# MCXA156 register map
Vendor: nxp.com; File version: 1.0
CPU: CM33 r2p0, little endian, no MPU, FPU, VTOR, 3 interrupt priority bits
Registers are 32-bit, read-write, reset 0x0 unless marked. A register's access mark holds for its fields unless they carry their own. Offsets are from the block's base; [hi:lo] are bit positions; {n}, {i} and the like mark numbered series.

## CMP0 — LPCMP
Base 0x400B1000
Same registers: CMP1 0x400B2000
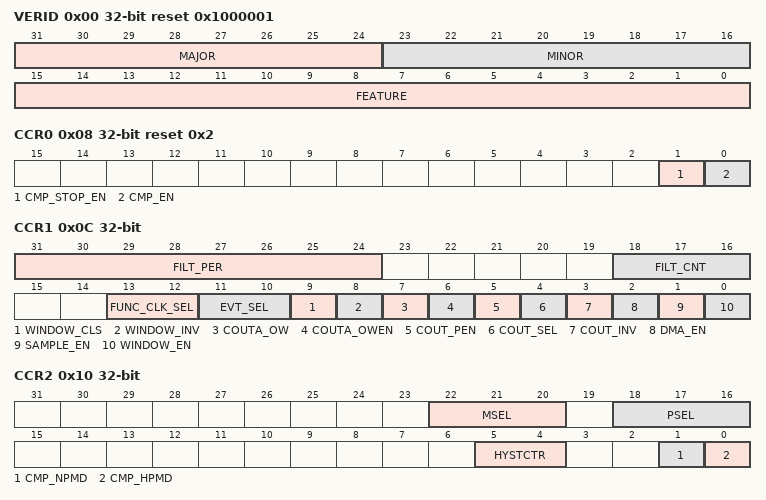
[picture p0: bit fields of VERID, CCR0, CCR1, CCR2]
0x00 VERID ro reset 0x1000001 — Version ID
  [31:24] MAJOR — Major Version Number
  [23:16] MINOR — Minor Version Number
  [15:0] FEATURE — Feature Specification Number
    1=ROUND_ROBIN (Round robin feature)
0x04 PARAM ro reset 0x2 — Parameter
  [3:0] DAC_RES — DAC Resolution
    0=RESO_4 (4-bit DAC); 1=RESO_6 (6-bit DAC); 2=RESO_8 (8-bit DAC); 3=RESO_10 (10-bit DAC); 4=RESO_12 (12-bit DAC); 5=RESO_14 (14-bit DAC); 6=RESO_16 (16-bit DAC)
0x08 CCR0 reset 0x2 — Comparator Control Register 0
  [1] CMP_STOP_EN — Comparator Deep Sleep Mode Enable
    0=DISABLE (Disables the analog comparator regardless of CMP_EN.); 1=ENABLE (Allows CMP_EN to enable the analog comparator.)
  [0] CMP_EN — Comparator Enable
    0=DISABLE (Disable (The analog logic remains off and consumes no power.)); 1=ENABLE
0x0C CCR1 — Comparator Control Register 1
  [31:24] FILT_PER — Filter Sample Period
  [18:16] FILT_CNT — Filter Sample Count
    0=BYPASSED (Filter is bypassed: COUT = COUTA); 1=SAMPLE_1 (1 consecutive sample (Comparator output is simply sampled.)); {v}=SAMPLE_{v} ({v} consecutive samples) (v=2..7)
  [13:12] FUNC_CLK_SEL — Functional Clock Source Select
    {v}=FUNC{v} (Select functional clock source {v}) (v=0..3)
  [11:10] EVT_SEL — COUT Event Select
    0=RISING (Rising edge); 1=FALLING (Falling edge); 0b1x=BOTH (Both edges)
  [9] WINDOW_CLS — COUT Event Window Close
    0=NO_CLOSE (COUT event cannot close the window); 1=CLOSE (COUT event can close the window)
  [8] WINDOW_INV — WINDOW/SAMPLE Signal Invert
    0=NO_INVERT (Do not invert); 1=INVERT
  [7] COUTA_OW — COUTA Output Level for Closed Window
    0=COUTA_0 (COUTA is 0); 1=COUTA_1 (COUTA is 1)
  [6] COUTA_OWEN — COUTA_OW Enable
    0=SAMPLED (COUTA holds the last sampled value.); 1=COUTA_OW (Enables the COUTA signal value to be defined by COUTA_OW.)
  [5] COUT_PEN — Comparator Output Pin Enable
    0=UNAVAILABLE (Not available); 1=AVAILABLE
  [4] COUT_SEL — Comparator Output Select
    0=COUT (Use COUT (filtered)); 1=COUTA (Use COUTA (unfiltered))
  [3] COUT_INV — Comparator Invert
    0=NO_INVERT (Do not invert); 1=INVERT
  [2] DMA_EN — DMA Enable
    0=DISABLE; 1=ENABLE
  [1] SAMPLE_EN — Sampling Enable
    0=DISABLE; 1=ENABLE
  [0] WINDOW_EN — Windowing Enable
    0=DISABLE; 1=ENABLE
0x10 CCR2 — Comparator Control Register 2
  [22:20] MSEL — Minus Input MUX Select
    {v}=INPUT_{v} (Input {v}m) (v=0..5); 7=INPUT_7 (Internal DAC output)
  [18:16] PSEL — Plus Input MUX Select
    {v}=INPUT_{v} (Input {v}p) (v=0..5); 7=INPUT_7 (Internal DAC output)
  [5:4] HYSTCTR — Comparator Hysteresis Control
    0=LEVEL_0 (Level 0: Analog comparator hysteresis 0 mV.); 1=LEVEL_1 (Level 1: Analog comparator hysteresis 10 mV.); 2=LEVEL_2 (Level 2: Analog comparator hysteresis 20 mV.); 3=LEVEL_3 (Level 3: Analog comparator hysteresis 30 mV.)
  [1] CMP_NPMD — CMP Nano Power Mode Select
    0=NO_NANO (Disables CMP Nano power mode. CCR2[CMP_HPMD] determines the mode for the comparator.); 1=NANO (Enables CMP Nano power mode.)
  [0] CMP_HPMD — CMP High Power Mode Select
    0=LOW (Low power (speed) comparison mode); 1=HIGH (High power (speed) comparison mode)
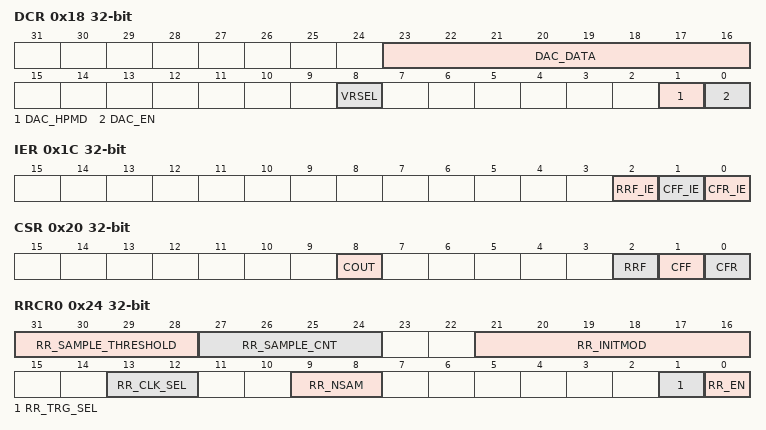
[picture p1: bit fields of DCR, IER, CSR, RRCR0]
0x18 DCR — DAC Control
  [23:16] DAC_DATA — DAC Output Voltage Select
  [8] VRSEL — DAC Reference High Voltage Source Select
    0=VREF0 (VREFH0); 1=VREF1 (VREFH1)
  [1] DAC_HPMD — DAC High Power Mode
    0=DISABLE; 1=ENABLE
  [0] DAC_EN — DAC Enable
    0=DISABLE; 1=ENABLE
0x1C IER — Interrupt Enable
  [2] RRF_IE — Round-Robin Flag Interrupt Enable
    0=DISABLE (Disables the round-robin flag interrupt.); 1=ENABLE (Enables the round-robin flag interrupt when the comparison result changes for a given channel.)
  [1] CFF_IE — Comparator Flag Falling Interrupt Enable
    0=DISABLE (Disables the comparator flag falling interrupt.); 1=ENABLE (Enables the comparator flag falling interrupt when CFF is set.)
  [0] CFR_IE — Comparator Flag Rising Interrupt Enable
    0=DISABLE (Disables the comparator flag rising interrupt.); 1=ENABLE (Enables the comparator flag rising interrupt when CFR is set.)
0x20 CSR — Comparator Status
  [8] COUT ro — Analog Comparator Output
  [2] RRF write-1-clears — Round-Robin Flag
    0=NOT_DETECTED; 1=DETECTED
  [1] CFF write-1-clears — Analog Comparator Flag Falling
    0=NOT_DETECTED; 1=DETECTED
  [0] CFR write-1-clears — Analog Comparator Flag Rising
    0=NOT_DETECTED; 1=DETECTED
0x24 RRCR0 — Round Robin Control Register 0
  [31:28] RR_SAMPLE_THRESHOLD — Sample Time Threshold
    {v}=SAMPLE_{v} (At least {v+1} sampled "1", the final result is "1") (v=0..15)
  [27:24] RR_SAMPLE_CNT — Number of Sample for One Channel
    {v}=SAMPLE_{v} ({v+1} samples) (v=0..15)
  [21:16] RR_INITMOD — Initialization Delay Modulus
    0=MOD_63 (63 cycles (same as 111111b)); {v}=MOD_1_63_{v} (1 to 63 cycles) (v=1..9)
  [13:12] RR_CLK_SEL — Round Robin Clock Source Select
    {v}=RR{v} (Select Round Robin clock Source {v}) (v=0..3)
  [9:8] RR_NSAM — Number of Sample Clocks
    0=WAIT_0 (0 clock); 1=WAIT_1 (1 clock); 2=WAIT_2 (2 clocks); 3=WAIT_3 (3 clocks)
  [1] RR_TRG_SEL — Round-Robin Trigger Select
    0=ENABLE (External trigger); 1=DISABLE (Internal trigger)
  [0] RR_EN — Round-Robin Enable
    0=DISABLE; 1=ENABLE
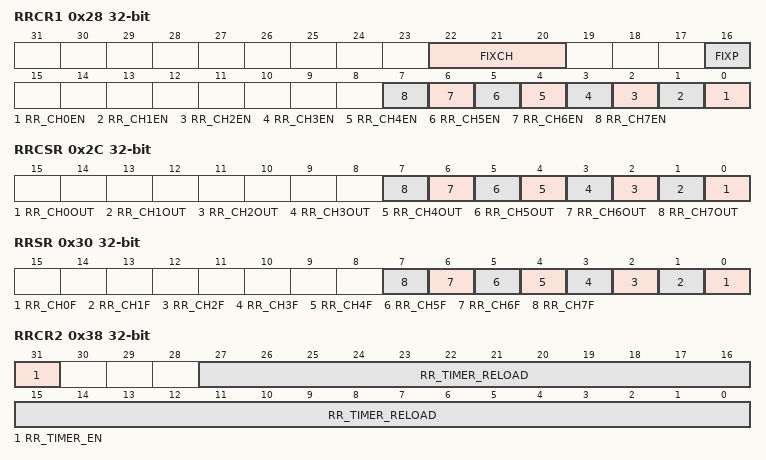
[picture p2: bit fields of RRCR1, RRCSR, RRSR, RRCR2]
0x28 RRCR1 — Round Robin Control Register 1
  [22:20] FIXCH — Fixed Channel Select
    {v}=FIX_CH{v} (Channel {v}) (v=0..7)
  [16] FIXP — Fixed Port
    0=FIX_PLUS (Fix the plus port. Sweep only the inputs to the minus port.); 1=FIX_MINUS (Fix the minus port. Sweep only the inputs to the plus port.)
  [n] RR_CH{n}EN (n=0..7) — Channel {n} Input Enable in Trigger Mode
    0=DISABLE; 1=ENABLE
0x2C RRCSR — Round Robin Control and Status
  [n] RR_CH{n}OUT (n=0..7) — Comparison Result for Channel {n}
0x30 RRSR write-1-clears — Round Robin Status
  [all] fields
    0=NOT_DIFFERENT (No different); 1=DIFFERENT
  [n] RR_CH{n}F write-1-clears (n=0..7) — Channel {n} Input Changed Flag
0x38 RRCR2 — Round Robin Control Register 2
  [31] RR_TIMER_EN — Round-Robin Internal Timer Enable
    0=DISABLE (Disables); 1=ENABLE (Enables)
  [27:0] RR_TIMER_RELOAD — Number of Sample Clocks
